AUTOSAR XML (schema 00050)
package /Components
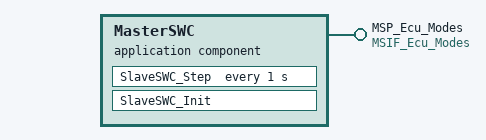
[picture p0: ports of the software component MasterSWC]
  application sw component type MasterSWC
    provide port MSP_Ecu_Modes: provided-interface=MSIF_Ecu_Modes
    behavior MasterSWC_IB: data-type-mapping=MasterSWCDataTypeMappingsSet, handle-termination-and-restart=NO-SUPPORT
      timing event TE_SlaveSWC_Step: start-on-event=SlaveSWC_Step, period=1
      runnable SlaveSWC_Init
        mode switch point OUT_MSP_Ecu_Modes_MG_Ecu_Modes: mode-group=MSP_Ecu_Modes.MG_Ecu_Modes
      runnable SlaveSWC_Step
        mode switch point OUT_MSP_Ecu_Modes_MG_Ecu_Modes: mode-group=MSP_Ecu_Modes.MG_Ecu_Modes
